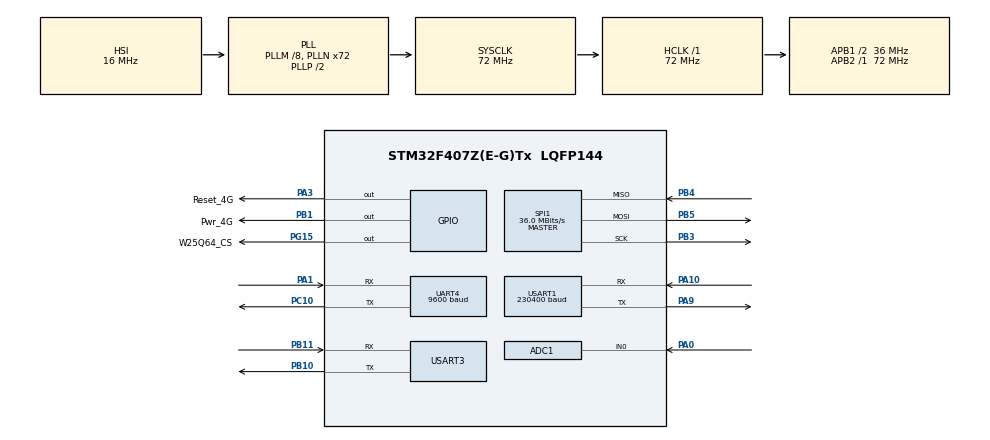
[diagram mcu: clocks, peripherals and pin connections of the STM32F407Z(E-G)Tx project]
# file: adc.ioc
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ADC1.Channel-0\#ChannelRegularConversion=ADC_CHANNEL_0
ADC1.ClockPrescaler=ADC_CLOCK_SYNC_PCLK_DIV2
ADC1.ContinuousConvMode=ENABLE
ADC1.DMAContinuousRequests=ENABLE
ADC1.DataAlign=ADC_DATAALIGN_RIGHT
ADC1.NbrOfConversion=1
ADC1.NbrOfConversionFlag=1
ADC1.Rank-0\#ChannelRegularConversion=1
ADC1.SamplingTime-0\#ChannelRegularConversion=ADC_SAMPLETIME_480CYCLES
ADC1.master=1
Dma.ADC1.0.Direction=DMA_PERIPH_TO_MEMORY
Dma.ADC1.0.FIFOMode=DMA_FIFOMODE_DISABLE
Dma.ADC1.0.Instance=DMA2_Stream0
Dma.ADC1.0.MemDataAlignment=DMA_MDATAALIGN_HALFWORD
Dma.ADC1.0.MemInc=DMA_MINC_ENABLE
Dma.ADC1.0.Mode=DMA_CIRCULAR
Dma.ADC1.0.PeriphDataAlignment=DMA_PDATAALIGN_HALFWORD
Dma.ADC1.0.PeriphInc=DMA_PINC_DISABLE
Dma.ADC1.0.Priority=DMA_PRIORITY_VERY_HIGH
Dma.Request0=ADC1
Dma.Request1=USART3_RX
Dma.USART3_RX.1.Direction=DMA_PERIPH_TO_MEMORY
Dma.USART3_RX.1.FIFOMode=DMA_FIFOMODE_DISABLE
Dma.USART3_RX.1.Instance=DMA1_Stream1
Dma.USART3_RX.1.MemDataAlignment=DMA_MDATAALIGN_BYTE
Dma.USART3_RX.1.MemInc=DMA_MINC_ENABLE
Dma.USART3_RX.1.Mode=DMA_NORMAL
Dma.USART3_RX.1.PeriphDataAlignment=DMA_PDATAALIGN_BYTE
Dma.USART3_RX.1.PeriphInc=DMA_PINC_DISABLE
Dma.USART3_RX.1.Priority=DMA_PRIORITY_MEDIUM
FREERTOS.Queues01=Adcqueue01,10,float,0,Dynamic,NULL,NULL
FREERTOS.Tasks01=DataprocessTask,24,256,StartDataprocessTask,As weak,NULL,Dynamic,NULL,NULL;Usart1Task,24,256,StartUsart1Task,As weak,NULL,Dynamic,NULL,NULL;BlueTask,24,256,StartBlueTask,As weak,NULL,Dynamic,NULL,NULL;EC200task,8,1024,StartEC200task,As weak,NULL,Dynamic,NULL,NULL
FREERTOS.configENABLE_FPU=1
Mcu.Family=STM32F4
Mcu.Name=STM32F407Z(E-G)Tx
Mcu.Package=LQFP144
NVIC.DMA1_Stream1_IRQn=true\:5\:0\:false\:false\:true\:true\:false\:true\:true
NVIC.DMA2_Stream0_IRQn=true\:5\:0\:false\:false\:true\:true\:false\:true\:true
NVIC.PriorityGroup=NVIC_PRIORITYGROUP_4
NVIC.TIM7_IRQn=true\:15\:0\:false\:false\:true\:false\:false\:true\:true
NVIC.TimeBase=TIM7_IRQn
NVIC.TimeBaseIP=TIM7
NVIC.USART3_IRQn=true\:5\:0\:false\:false\:true\:true\:true\:true\:true
PA0-WKUP.Signal=ADCx_IN0
PA1.Mode=Asynchronous
PA1.Signal=UART4_RX
PA10.Mode=Asynchronous
PA10.Signal=USART1_RX
PA13.Mode=Serial_Wire
PA13.Signal=SYS_JTMS-SWDIO
PA14.Mode=Serial_Wire
PA14.Signal=SYS_JTCK-SWCLK
PA3.GPIO_Label=Reset_4G
PA3.Signal=GPIO_Output
PA9.Mode=Asynchronous
PA9.Signal=USART1_TX
PB1.GPIO_Label=Pwr_4G
PB1.Signal=GPIO_Output
PB10.Mode=Asynchronous
PB10.Signal=USART3_TX
PB11.Mode=Asynchronous
PB11.Signal=USART3_RX
PB3.Mode=Full_Duplex_Master
PB3.Signal=SPI1_SCK
PB4.Mode=Full_Duplex_Master
PB4.Signal=SPI1_MISO
PB5.Mode=Full_Duplex_Master
PB5.Signal=SPI1_MOSI
PC10.Mode=Asynchronous
PC10.Signal=UART4_TX
PG15.GPIO_Label=W25Q64_CS
PG15.Signal=GPIO_Output
ProjectManager.HeapSize=0x200
ProjectManager.StackSize=0x400
ProjectManager.TargetToolchain=CMake
RCC.48MHZClocksFreq_Value=36000000
RCC.AHBFreq_Value=72000000
RCC.APB1CLKDivider=RCC_HCLK_DIV2
RCC.APB1Freq_Value=36000000
RCC.APB1TimFreq_Value=72000000
RCC.APB2Freq_Value=72000000
RCC.APB2TimFreq_Value=72000000
RCC.CortexFreq_Value=72000000
RCC.HCLKFreq_Value=72000000
RCC.HSE_VALUE=25000000
RCC.HSI_VALUE=16000000
RCC.LSE_VALUE=32768
RCC.PLLM=8
RCC.PLLN=72
RCC.SYSCLKFreq_VALUE=72000000
RCC.SYSCLKSource=RCC_SYSCLKSOURCE_PLLCLK
RCC.VCOOutputFreq_Value=144000000
SH.ADCx_IN0.0=ADC1_IN0,IN0
SPI1.CalculateBaudRate=36.0 MBits/s
SPI1.Direction=SPI_DIRECTION_2LINES
SPI1.Mode=SPI_MODE_MASTER
SPI1.VirtualType=VM_MASTER
UART4.BaudRate=9600
UART4.VirtualMode=Asynchronous
USART1.BaudRate=230400
USART1.VirtualMode=VM_ASYNC
USART3.VirtualMode=VM_ASYNC
VP_FREERTOS_VS_CMSIS_V2.Mode=CMSIS_V2
VP_SYS_VS_tim7.Mode=TIM7
board=custom

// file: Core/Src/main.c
/* USER CODE BEGIN Header */
/**
 ******************************************************************************
 * @file           : main.c
 * @brief          : Main program body
 ******************************************************************************
 * @attention
 *
 * Copyright (c) 2026 STMicroelectronics.
 * All rights reserved.
 *
 * This software is licensed under terms that can be found in the LICENSE file
 * in the root directory of this software component.
 * If no LICENSE file comes with this software, it is provided AS-IS.
 *
 ******************************************************************************
 */
/* USER CODE END Header */
#include "main.h"
#include "cmsis_os.h"
#include "adc.h"
#include "dma.h"
#include "spi.h"
#include "usart.h"
#include "gpio.h"

/* USER CODE BEGIN PD */
uint32_t ADC_data[10] = {0};
OTA_INFO OTA_info;
/* USER CODE END PD */

void SystemClock_Config(void);
void MX_FREERTOS_Init(void);

int main(void)
{

  /* MCU Configuration--------------------------------------------------------*/

  /* Reset of all peripherals, Initializes the Flash interface and the Systick. */
  HAL_Init();

  /* Configure the system clock */
  SystemClock_Config();

  /* Initialize all configured peripherals */
  MX_GPIO_Init();
  MX_DMA_Init();
  MX_ADC1_Init();
  MX_UART4_Init();
  MX_USART1_UART_Init();
  MX_USART3_UART_Init();
  MX_SPI1_Init();
  /* USER CODE BEGIN 2 */
  PQ_Init(&message);
  HAL_ADC_Start_DMA(&hadc1, ADC_data, 10);
  __HAL_DMA_DISABLE_IT(&hdma_adc1, DMA_IT_HT);
  HAL_GPIO_WritePin(Reset_4G_GPIO_Port, Reset_4G_Pin, GPIO_PIN_SET);
  HAL_Delay(pdMS_TO_TICKS(100));
  HAL_GPIO_WritePin(Reset_4G_GPIO_Port, Reset_4G_Pin, GPIO_PIN_RESET);
  HAL_UARTEx_ReceiveToIdle_DMA(&huart3, AT_Recive, sizeof(AT_Recive));
  // 关闭DMA传输过半中断（HAL库默认开启，但我们只需要接收完成中断）
  __HAL_DMA_DISABLE_IT(huart3.hdmarx, DMA_IT_HT);

  /* USER CODE END 2 */

  /* Init scheduler */
  osKernelInitialize();  /* Call init function for freertos objects (in cmsis_os2.c) */
  MX_FREERTOS_Init();

  /* Start scheduler */
  osKernelStart();

  /* We should never get here as control is now taken by the scheduler */

  /* Infinite loop */
    while (1) {

    }
}

void SystemClock_Config(void)
{
  RCC_OscInitTypeDef RCC_OscInitStruct = {0};
  RCC_ClkInitTypeDef RCC_ClkInitStruct = {0};

  /** Configure the main internal regulator output voltage
  */
  __HAL_RCC_PWR_CLK_ENABLE();
  __HAL_PWR_VOLTAGESCALING_CONFIG(PWR_REGULATOR_VOLTAGE_SCALE1);

  /** Initializes the RCC Oscillators according to the specified parameters
  * in the RCC_OscInitTypeDef structure.
  */
  RCC_OscInitStruct.OscillatorType = RCC_OSCILLATORTYPE_HSI;
  RCC_OscInitStruct.HSIState = RCC_HSI_ON;
  RCC_OscInitStruct.HSICalibrationValue = RCC_HSICALIBRATION_DEFAULT;
  RCC_OscInitStruct.PLL.PLLState = RCC_PLL_ON;
  RCC_OscInitStruct.PLL.PLLSource = RCC_PLLSOURCE_HSI;
  RCC_OscInitStruct.PLL.PLLM = 8;
  RCC_OscInitStruct.PLL.PLLN = 72;
  RCC_OscInitStruct.PLL.PLLP = RCC_PLLP_DIV2;
  RCC_OscInitStruct.PLL.PLLQ = 4;
  if (HAL_RCC_OscConfig(&RCC_OscInitStruct) != HAL_OK)
  {
    Error_Handler();
  }

  /** Initializes the CPU, AHB and APB buses clocks
  */
  RCC_ClkInitStruct.ClockType = RCC_CLOCKTYPE_HCLK|RCC_CLOCKTYPE_SYSCLK
                              |RCC_CLOCKTYPE_PCLK1|RCC_CLOCKTYPE_PCLK2;
  RCC_ClkInitStruct.SYSCLKSource = RCC_SYSCLKSOURCE_PLLCLK;
  RCC_ClkInitStruct.AHBCLKDivider = RCC_SYSCLK_DIV1;
  RCC_ClkInitStruct.APB1CLKDivider = RCC_HCLK_DIV2;
  RCC_ClkInitStruct.APB2CLKDivider = RCC_HCLK_DIV1;

  if (HAL_RCC_ClockConfig(&RCC_ClkInitStruct, FLASH_LATENCY_2) != HAL_OK)
  {
    Error_Handler();
  }
}

void HAL_TIM_PeriodElapsedCallback(TIM_HandleTypeDef *htim)
{
  if (htim->Instance == TIM7)
  {
    HAL_IncTick();
  }
}

void Error_Handler(void)
{
    __disable_irq();
    while (1) {
    }
}

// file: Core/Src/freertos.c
/* USER CODE BEGIN Header */
/**
  ******************************************************************************
  * File Name          : freertos.c
  * Description        : Code for freertos applications
  ******************************************************************************
  * @attention
  *
  * Copyright (c) 2026 STMicroelectronics.
  * All rights reserved.
  *
  * This software is licensed under terms that can be found in the LICENSE file
  * in the root directory of this software component.
  * If no LICENSE file comes with this software, it is provided AS-IS.
  *
  ******************************************************************************
  */
/* USER CODE END Header */

#include "FreeRTOS.h"
#include "task.h"
#include "main.h"
#include "cmsis_os.h"

/* Definitions for DataprocessTask */
osThreadId_t DataprocessTaskHandle;
const osThreadAttr_t DataprocessTask_attributes = {
  .name = "DataprocessTask",
  .stack_size = 256 * 4,
  .priority = (osPriority_t) osPriorityNormal,
};
/* Definitions for Usart1Task */
osThreadId_t Usart1TaskHandle;
const osThreadAttr_t Usart1Task_attributes = {
  .name = "Usart1Task",
  .stack_size = 256 * 4,
  .priority = (osPriority_t) osPriorityNormal,
};
/* Definitions for BlueTask */
osThreadId_t BlueTaskHandle;
const osThreadAttr_t BlueTask_attributes = {
  .name = "BlueTask",
  .stack_size = 256 * 4,
  .priority = (osPriority_t) osPriorityNormal,
};
/* Definitions for EC200task */
osThreadId_t EC200taskHandle;
const osThreadAttr_t EC200task_attributes = {
  .name = "EC200task",
  .stack_size = 1024 * 4,
  .priority = (osPriority_t) osPriorityLow,
};
/* Definitions for Adcqueue01 */
osMessageQueueId_t Adcqueue01Handle;
const osMessageQueueAttr_t Adcqueue01_attributes = {
  .name = "Adcqueue01"
};

void StartDataprocessTask(void *argument);
void StartUsart1Task(void *argument);
void StartBlueTask(void *argument);
void StartEC200task(void *argument);

void MX_FREERTOS_Init(void); /* (MISRA C 2004 rule 8.1) */

void MX_FREERTOS_Init(void) {

  /* Create the queue(s) */
  /* creation of Adcqueue01 */
  Adcqueue01Handle = osMessageQueueNew (10, sizeof(float), &Adcqueue01_attributes);

  /* Create the thread(s) */
  /* creation of DataprocessTask */
  DataprocessTaskHandle = osThreadNew(StartDataprocessTask, NULL, &DataprocessTask_attributes);

  /* creation of Usart1Task */
  Usart1TaskHandle = osThreadNew(StartUsart1Task, NULL, &Usart1Task_attributes);

  /* creation of BlueTask */
  BlueTaskHandle = osThreadNew(StartBlueTask, NULL, &BlueTask_attributes);

  /* creation of EC200task */
  EC200taskHandle = osThreadNew(StartEC200task, NULL, &EC200task_attributes);

}

__weak void StartDataprocessTask(void *argument)
{
  for(;;)
  {
    osDelay(1);
  }
}

__weak void StartUsart1Task(void *argument)
{
  for(;;)
  {
    osDelay(1);
  }
}

__weak void StartBlueTask(void *argument)
{
  for(;;)
  {
    osDelay(1);
  }
}

__weak void StartEC200task(void *argument)
{
  for(;;)
  {
    osDelay(1);
  }
}
